# STM32F103xG register map
File version: 1.0
Registers are 32-bit, read-write, reset 0x0 unless marked. A register's access mark holds for its fields unless they carry their own. Offsets are from the block's base; [hi:lo] are bit positions; 'fields as' and 'values as' point back to an identical list.

## FLASH — FLASH Registers
Base 0x40022000
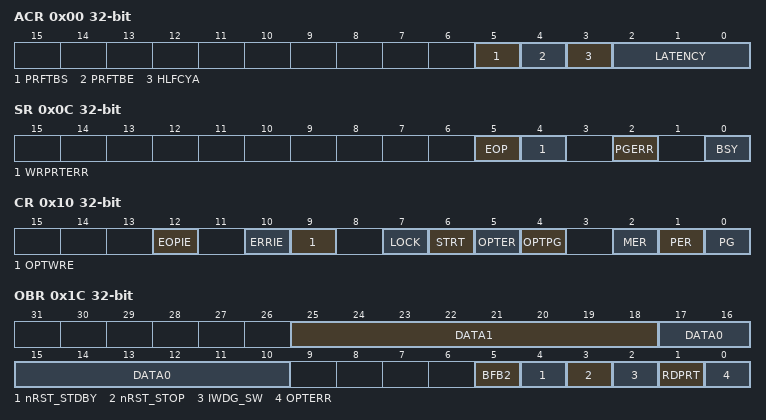
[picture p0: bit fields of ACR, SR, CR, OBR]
0x00 ACR
  [5] PRFTBS — Prefetch Buffer Status
  [4] PRFTBE — Prefetch Buffer Enable
  [3] HLFCYA — Flash Half Cycle Access Enable
  [2:0] LATENCY — LATENCY[2:0] bits (Latency)
    0=FLASH Zero Latency cycle; 1=FLASH One Latency cycle; 2=FLASH Two wait states
0x04 KEYR
  [31:0] FKEYR — FPEC Key
0x08 OPTKEYR
  [31:0] OPTKEYR — Option Byte Key
0x0C SR
  [5] EOP — End of operation
  [4] WRPRTERR — Write Protection Error
  [2] PGERR — Programming Error
  [0] BSY — Busy
0x10 CR
  [12] EOPIE — End of operation interrupt enable
  [10] ERRIE — Error Interrupt Enable
  [9] OPTWRE — Option Bytes Write Enable
  [7] LOCK
  [6] STRT — Start
  [5] OPTER — Option Byte Erase
  [4] OPTPG — Option Byte Programming
  [2] MER — Mass Erase
  [1] PER — Page Erase
  [0] PG — Programming
0x14 AR
  [31:0] FAR — Flash Address
0x1C OBR
  [25:18] DATA1
  [17:10] DATA0
  [5] BFB2
  [4] nRST_STDBY
  [3] nRST_STOP
  [2] IWDG_SW
  [1] RDPRT — Read protection
  [0] OPTERR — Option Byte Error
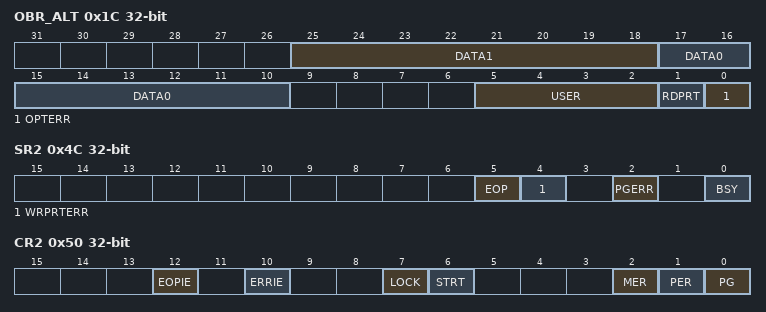
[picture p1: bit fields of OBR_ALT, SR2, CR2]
0x1C OBR_ALT (alternate view of OBR)
  [25:18] DATA1
  [17:10] DATA0
  [5:2] USER — User Option Bytes
  [1] RDPRT — Read protection
  [0] OPTERR — Option Byte Error
0x20 WRPR
  [31:0] WRP — Write Protect
0x44 KEYR2
  [31:0] FKEYR — FPEC Key
0x4C SR2
  fields as SR
0x50 CR2
  [12] EOPIE — End of operation interrupt enable
  [10] ERRIE — Error Interrupt Enable
  [7] LOCK
  [6] STRT — Start
  [2] MER — Mass Erase
  [1] PER — Page Erase
  [0] PG — Programming
0x54 AR2
  [31:0] FAR — Flash Address

## CRC — CRC calculation unit
Base 0x40023000
0x00 DR — CRC Data register
  [31:0] DR — Data register bits
0x04 IDR 8-bit — CRC Independent data register
  [7:0] IDR — General-purpose 8-bit data register bits
0x08 CR — CRC Control register
  [0] RESET — RESET bit

## FSMC
Base 0xA0000000
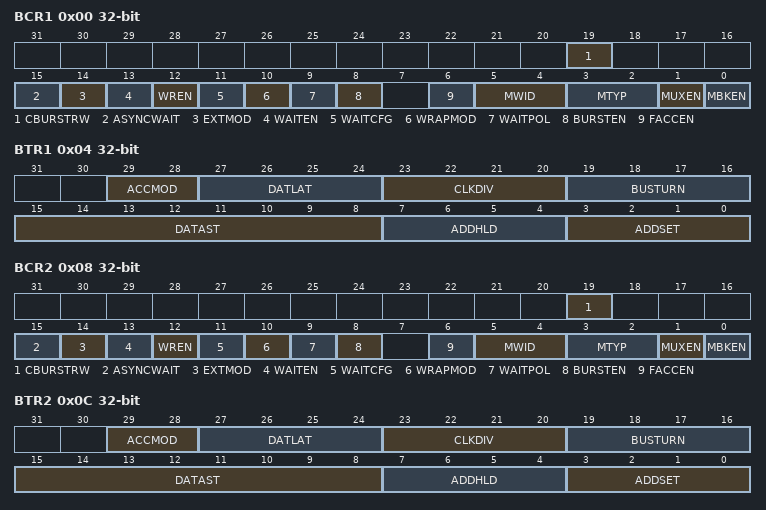
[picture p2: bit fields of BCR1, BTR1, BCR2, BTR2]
0x00 BCR1
  [19] CBURSTRW — Write burst enable
  [15] ASYNCWAIT — Asynchronous wait
  [14] EXTMOD — Extended mode enable
  [13] WAITEN — Wait enable bit
  [12] WREN — Write enable bit
  [11] WAITCFG — Wait timing configuration
  [10] WRAPMOD — Wrapped burst mode support
  [9] WAITPOL — Wait signal polarity bit
  [8] BURSTEN — Burst enable bit
  [6] FACCEN — Flash access enable
  [5:4] MWID — MWID[1:0] bits (Memory data bus width)
  [3:2] MTYP — MTYP[1:0] bits (Memory type)
  [1] MUXEN — Address/data multiplexing enable bit
  [0] MBKEN — Memory bank enable bit
0x04 BTR1
  [29:28] ACCMOD — ACCMOD[1:0] bits (Access mode)
  [27:24] DATLAT — DATLA[3:0] bits (Data latency)
  [23:20] CLKDIV — CLKDIV[3:0] bits (Clock divide ratio)
  [19:16] BUSTURN — BUSTURN[3:0] bits (Bus turnaround phase duration)
  [15:8] DATAST — DATAST [3:0] bits (Data-phase duration)
  [7:4] ADDHLD — ADDHLD[3:0] bits (Address-hold phase duration)
  [3:0] ADDSET — ADDSET[3:0] bits (Address setup phase duration)
0x08 BCR2
  fields as BCR1
0x0C BTR2
  fields as BTR1
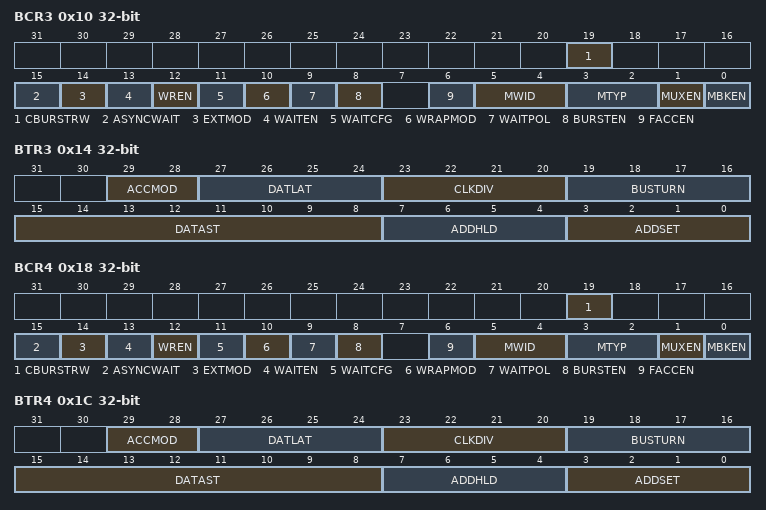
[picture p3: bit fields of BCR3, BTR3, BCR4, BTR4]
0x10 BCR3
  fields as BCR1
0x14 BTR3
  fields as BTR1
0x18 BCR4
  fields as BCR1
0x1C BTR4
  fields as BTR1
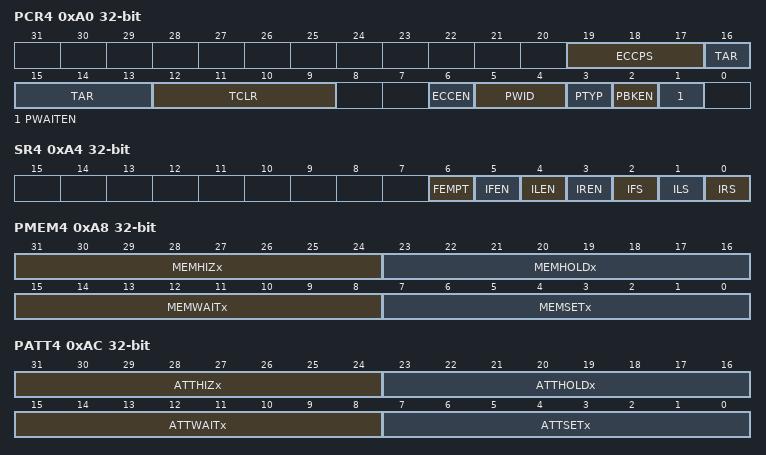
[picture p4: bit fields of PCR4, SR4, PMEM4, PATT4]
0xA0 PCR4
  [19:17] ECCPS — ECCPS[1:0] bits (ECC page size)
  [16:13] TAR — TAR[3:0] bits (ALE to RE delay)
  [12:9] TCLR — TCLR[3:0] bits (CLE to RE delay)
  [6] ECCEN — ECC computation logic enable bit
  [5:4] PWID — PWID[1:0] bits (NAND Flash databus width)
  [3] PTYP — Memory type
  [2] PBKEN — PC Card/NAND Flash memory bank enable bit
  [1] PWAITEN — Wait feature enable bit
0xA4 SR4
  [6] FEMPT — FIFO empty
  [5] IFEN — Interrupt Falling Edge detection Enable bit
  [4] ILEN — Interrupt Level detection Enable bit
  [3] IREN — Interrupt Rising Edge detection Enable bit
  [2] IFS — Interrupt Falling Edge status
  [1] ILS — Interrupt Level status
  [0] IRS — Interrupt Rising Edge status
0xA8 PMEM4
  [31:24] MEMHIZx — MEMHIZx[7:0] bits (Common memory x databus HiZ time)
  [23:16] MEMHOLDx — MEMHOLDx[7:0] bits (Common memory x hold time)
  [15:8] MEMWAITx — MEMWAITx[7:0] bits (Common memory x wait time)
  [7:0] MEMSETx — MEMSETx[7:0] bits (Common memory x setup time)
0xAC PATT4
  [31:24] ATTHIZx — ATTHIZx[7:0] bits (Attribute memory x databus HiZ time)
  [23:16] ATTHOLDx — ATTHOLDx[7:0] bits (Attribute memory x hold time)
  [15:8] ATTWAITx — ATTWAITx[7:0] bits (Attribute memory x wait time)
  [7:0] ATTSETx — ATTSETx[7:0] bits (Attribute memory x setup time)
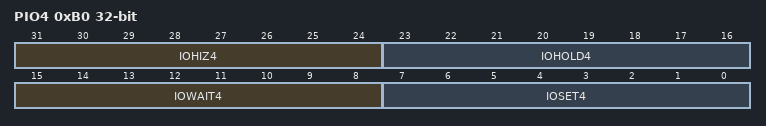
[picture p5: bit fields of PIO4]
0xB0 PIO4
  [31:24] IOHIZ4 — IOHIZ4[7:0] bits (I/O 4 databus HiZ time)
  [23:16] IOHOLD4 — IOHOLD4[7:0] bits (I/O 4 hold time)
  [15:8] IOWAIT4 — IOWAIT4[7:0] bits (I/O 4 wait time)
  [7:0] IOSET4 — IOSET4[7:0] bits (I/O 4 setup time)
